# haltium_cellrf register map
Vendor: Nordic Semiconductor; Series: nRFHaltium; File version: 1
CPU: CM0 r0p0, little endian, no MPU, no FPU, 2 interrupt priority bits, 33 interrupts
Registers are 32-bit, read-write, reset 0x0 unless marked. A register's access mark holds for its fields unless they carry their own. Offsets are from the block's base; [hi:lo] are bit positions; 'fields as' and 'values as' point back to an identical list.

## RFSERVICES — AhmaRfSubsystem general control register map
Base 0x46045000
0x100 EVENTS_SYSTEMTIMERSYNC — Rising edge in synchronized SystemTimerSync signal
  [0] EVENTS_SYSTEMTIMERSYNC
    0=NotGenerated (Event not generated); 1=Generated (Event generated)
0x104 EVENTS_GNSSTIMERSYNC — Rising edge in synchronized gnssTimerSync signal
  [0] EVENTS_GNSSTIMERSYNC
    values as EVENTS_SYSTEMTIMERSYNC.EVENTS_SYSTEMTIMERSYNC
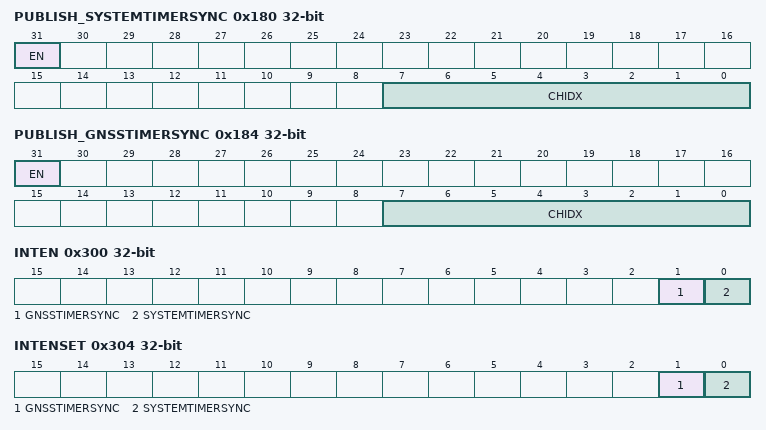
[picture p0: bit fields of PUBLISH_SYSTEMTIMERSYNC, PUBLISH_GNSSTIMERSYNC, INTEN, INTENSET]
0x180 PUBLISH_SYSTEMTIMERSYNC — Publish configuration for event SYSTEMTIMERSYNC
  [31] EN
    0=Disabled (Disable publishing); 1=Enabled (Enable publishing)
  [7:0] CHIDX — DPPI channel that event SYSTEMTIMERSYNC will publish to
0x184 PUBLISH_GNSSTIMERSYNC — Publish configuration for event GNSSTIMERSYNC
  [31] EN
    values as PUBLISH_SYSTEMTIMERSYNC.EN
  [7:0] CHIDX — DPPI channel that event GNSSTIMERSYNC will publish to
0x300 INTEN — Enable or disable interrupt
  [1] GNSSTIMERSYNC — Enable or disable interrupt for event GNSSTIMERSYNC
    0=Disabled; 1=Enabled
  [0] SYSTEMTIMERSYNC — Enable or disable interrupt for event SYSTEMTIMERSYNC
    0=Disabled; 1=Enabled
0x304 INTENSET — Enable interrupt
  [1] GNSSTIMERSYNC — Write '1' to enable interrupt for event GNSSTIMERSYNC
    on read: 0=Disabled (Read: Disabled); 1=Enabled (Read: Enabled) | on write: 1=Set (Enable)
  [0] SYSTEMTIMERSYNC — Write '1' to enable interrupt for event SYSTEMTIMERSYNC
    values as GNSSTIMERSYNC
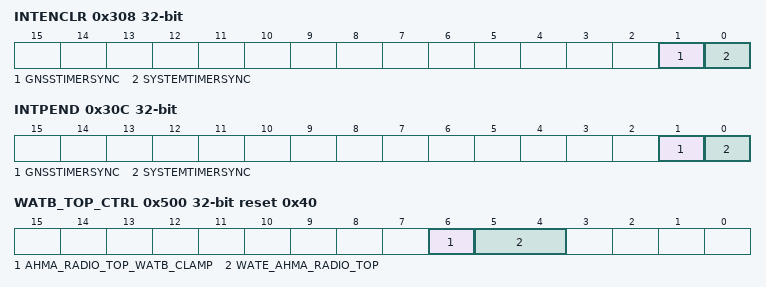
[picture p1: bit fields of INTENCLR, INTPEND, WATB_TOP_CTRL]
0x308 INTENCLR — Disable interrupt
  [1] GNSSTIMERSYNC — Write '1' to disable interrupt for event GNSSTIMERSYNC
    on read: 0=Disabled (Read: Disabled); 1=Enabled (Read: Enabled) | on write: 1=Clear (Disable)
  [0] SYSTEMTIMERSYNC — Write '1' to disable interrupt for event SYSTEMTIMERSYNC
    values as GNSSTIMERSYNC
0x30C INTPEND ro — Pending interrupts
  [1] GNSSTIMERSYNC — Read pending status of interrupt for event GNSSTIMERSYNC
    on read: 0=NotPending (Read: Not pending); 1=Pending (Read: Pending)
  [0] SYSTEMTIMERSYNC — Read pending status of interrupt for event SYSTEMTIMERSYNC
    values as GNSSTIMERSYNC
0x400 CKREQSTATUS ro reset 0x80008 — Clock request status
  [21:0] CKREQSTATUS — Clock request status for each peripheral
0x500 WATB_TOP_CTRL reset 0x40 — AHMA_ANA Top level test network control
  [6] AHMA_RADIO_TOP_WATB_CLAMP — Test network clamp control. Must be inactivated when top level test switches are on.
    0=Inactive (Clamp inactive); 1=Active (AHMA_ANA internal test network clamped to ground)
  [5:4] WATE_AHMA_RADIO_TOP — Top Level test switch enable
    0=Both_Off (Both WATB0 and WATB1 test switches in off state); 1=WATB0_On (AHMA_ANA WATB0 connected to corresponding GPIO analog slice); 2=WATB1_On (AHMA_ANA WATB1 connected to corresponding GPIO analog slice); 3=Both_On (Both WATB0 and WATB1 connected to corresponding GPIO analog slices)
0x504 CK_REQ_SYSTIMER — Starts RX digital filtering.
  [0] CK_REQ_SYSTIMER — Clock request control for a register that captures System Timer timemark input
0x508 POWERCLOCKMODE — Power and clock mode
  [1:0] POWERCLOCKMODE — Peripheral domain power and clock mode
    0=Power_Off (Peripheral domain is allowed to power off); 1=Clocks_Off (Peripheral domain is not allowed to power off, but is allowed to turn its clocks off); 2=Clocks_Gated (Peripheral domain is not allowed to power off, and its clock generators are kept running while the clocks themselves may be gated); 3=All_On (Peripheral domain is forced to have its clocks running)

## CPUCONF — CPU Configuration
Base 0x46013000
0x508 CPUSTART — Enable for starting the CPU
  [0] EN — Enable to start the CPU.
    0=Stopped (CPU stopped.); 1=Started (CPU started.)
